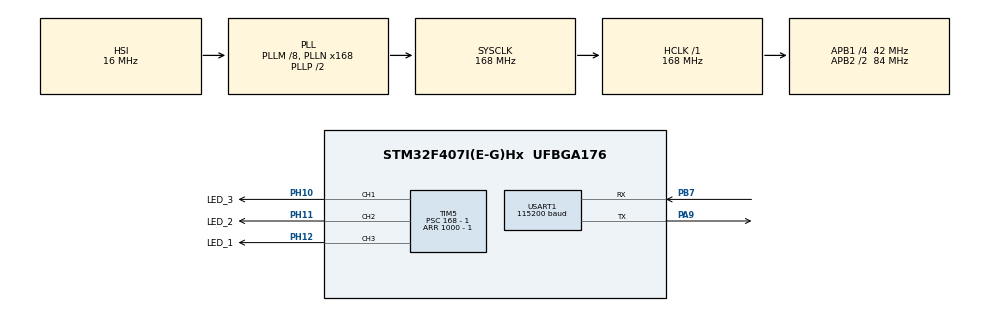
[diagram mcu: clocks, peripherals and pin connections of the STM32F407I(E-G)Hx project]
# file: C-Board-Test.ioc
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Dma.Request0=USART1_RX
Dma.Request1=USART1_TX
Dma.USART1_RX.0.Direction=DMA_PERIPH_TO_MEMORY
Dma.USART1_RX.0.FIFOMode=DMA_FIFOMODE_DISABLE
Dma.USART1_RX.0.Instance=DMA2_Stream2
Dma.USART1_RX.0.MemDataAlignment=DMA_MDATAALIGN_BYTE
Dma.USART1_RX.0.MemInc=DMA_MINC_ENABLE
Dma.USART1_RX.0.Mode=DMA_NORMAL
Dma.USART1_RX.0.PeriphDataAlignment=DMA_PDATAALIGN_BYTE
Dma.USART1_RX.0.PeriphInc=DMA_PINC_DISABLE
Dma.USART1_RX.0.Priority=DMA_PRIORITY_HIGH
Dma.USART1_TX.1.Direction=DMA_MEMORY_TO_PERIPH
Dma.USART1_TX.1.FIFOMode=DMA_FIFOMODE_DISABLE
Dma.USART1_TX.1.Instance=DMA2_Stream7
Dma.USART1_TX.1.MemDataAlignment=DMA_MDATAALIGN_BYTE
Dma.USART1_TX.1.MemInc=DMA_MINC_ENABLE
Dma.USART1_TX.1.Mode=DMA_NORMAL
Dma.USART1_TX.1.PeriphDataAlignment=DMA_PDATAALIGN_BYTE
Dma.USART1_TX.1.PeriphInc=DMA_PINC_DISABLE
Dma.USART1_TX.1.Priority=DMA_PRIORITY_HIGH
FREERTOS.Tasks01=defaultTask,24,128,StartDefaultTask,Default,NULL,Dynamic,NULL,NULL;Breath_LED,24,128,Breath_LED_Loop,As external,NULL,Dynamic,NULL,NULL;Messager,40,128,Messager_Loop,As external,NULL,Dynamic,NULL,NULL;Motion,24,128,Motion_Loop,As external,NULL,Dynamic,NULL,NULL;Light,24,128,Light_Loop,As external,NULL,Dynamic,NULL,NULL;Tof,48,128,Tof_Loop,As external,NULL,Dynamic,NULL,NULL
FREERTOS.configENABLE_FPU=1
FREERTOS.configUSE_NEWLIB_REENTRANT=1
Mcu.Family=STM32F4
Mcu.Name=STM32F407I(E-G)Hx
Mcu.Package=UFBGA176
NVIC.DMA2_Stream2_IRQn=true\:5\:0\:false\:false\:true\:true\:false\:true\:true
NVIC.DMA2_Stream7_IRQn=true\:5\:0\:false\:false\:true\:true\:false\:true\:true
NVIC.PriorityGroup=NVIC_PRIORITYGROUP_4
NVIC.TIM8_TRG_COM_TIM14_IRQn=true\:15\:0\:false\:false\:true\:false\:false\:true\:true
NVIC.TimeBase=TIM8_TRG_COM_TIM14_IRQn
NVIC.TimeBaseIP=TIM14
NVIC.USART1_IRQn=true\:5\:0\:false\:false\:true\:true\:true\:true\:true
PA13.Mode=Serial_Wire
PA13.Signal=SYS_JTMS-SWDIO
PA14.Mode=Serial_Wire
PA14.Signal=SYS_JTCK-SWCLK
PA9.Mode=Asynchronous
PA9.Signal=USART1_TX
PB7.Mode=Asynchronous
PB7.Signal=USART1_RX
PH0-OSC_IN.Mode=HSE-External-Oscillator
PH0-OSC_IN.Signal=RCC_OSC_IN
PH1-OSC_OUT.Mode=HSE-External-Oscillator
PH1-OSC_OUT.Signal=RCC_OSC_OUT
PH10.GPIO_Label=LED_3
PH10.Signal=S_TIM5_CH1
PH11.GPIO_Label=LED_2
PH11.Signal=S_TIM5_CH2
PH12.GPIO_Label=LED_1
PH12.Signal=S_TIM5_CH3
ProjectManager.HeapSize=0x200
ProjectManager.StackSize=0x400
ProjectManager.TargetToolchain=STM32CubeIDE
RCC.48MHZClocksFreq_Value=84000000
RCC.AHBFreq_Value=168000000
RCC.APB1CLKDivider=RCC_HCLK_DIV4
RCC.APB1Freq_Value=42000000
RCC.APB1TimFreq_Value=84000000
RCC.APB2CLKDivider=RCC_HCLK_DIV2
RCC.APB2Freq_Value=84000000
RCC.APB2TimFreq_Value=168000000
RCC.CortexFreq_Value=168000000
RCC.HCLKFreq_Value=168000000
RCC.HSE_VALUE=25000000
RCC.HSI_VALUE=16000000
RCC.LSE_VALUE=32768
RCC.PLLM=8
RCC.PLLN=168
RCC.SYSCLKFreq_VALUE=168000000
RCC.SYSCLKSource=RCC_SYSCLKSOURCE_PLLCLK
RCC.VCOOutputFreq_Value=336000000
SH.S_TIM5_CH1.0=TIM5_CH1,PWM Generation1 CH1
SH.S_TIM5_CH2.0=TIM5_CH2,PWM Generation2 CH2
SH.S_TIM5_CH3.0=TIM5_CH3,PWM Generation3 CH3
TIM5.AutoReloadPreload=TIM_AUTORELOAD_PRELOAD_ENABLE
TIM5.Channel-PWM\ Generation1\ CH1=TIM_CHANNEL_1
TIM5.Channel-PWM\ Generation2\ CH2=TIM_CHANNEL_2
TIM5.Channel-PWM\ Generation3\ CH3=TIM_CHANNEL_3
TIM5.Period=1000 - 1
TIM5.Prescaler=168 - 1
USART1.BaudRate=115200
USART1.VirtualMode=VM_ASYNC
VP_FREERTOS_VS_CMSIS_V2.Mode=CMSIS_V2
VP_SYS_VS_tim14.Mode=TIM14
VP_TIM5_VS_ClockSourceINT.Mode=Internal
board=custom

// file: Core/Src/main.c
/* USER CODE BEGIN Header */
/**
 ******************************************************************************
 * @file           : main.c
 * @brief          : Main program body
 ******************************************************************************
 * @attention
 *
 * Copyright (c) 2023 STMicroelectronics.
 * All rights reserved.
 *
 * This software is licensed under terms that can be found in the LICENSE file
 * in the root directory of this software component.
 * If no LICENSE file comes with this software, it is provided AS-IS.
 *
 ******************************************************************************
 */
/* USER CODE END Header */
#include "main.h"
#include "cmsis_os.h"
#include "dma.h"
#include "tim.h"
#include "usart.h"
#include "gpio.h"

void SystemClock_Config(void);
void MX_FREERTOS_Init(void);

int main(void)
{

    /* MCU Configuration--------------------------------------------------------*/

    /* Reset of all peripherals, Initializes the Flash interface and the Systick. */
    HAL_Init();

    /* Configure the system clock */
    SystemClock_Config();

    /* Initialize all configured peripherals */
    MX_GPIO_Init();
    MX_DMA_Init();
    MX_TIM5_Init();
    MX_USART1_UART_Init();
    /* USER CODE BEGIN 2 */
    HAL_TIM_PWM_Start(&htim5, TIM_CHANNEL_1);
    HAL_TIM_PWM_Start(&htim5, TIM_CHANNEL_2);
    HAL_TIM_PWM_Start(&htim5, TIM_CHANNEL_3);

    /* USER CODE END 2 */

    /* Init scheduler */
    osKernelInitialize(); /* Call init function for freertos objects (in freertos.c) */
    MX_FREERTOS_Init();

    /* Start scheduler */
    osKernelStart();

    /* We should never get here as control is now taken by the scheduler */
    /* Infinite loop */
    while (1) {

    }
}

void SystemClock_Config(void)
{
    RCC_OscInitTypeDef RCC_OscInitStruct = {0};
    RCC_ClkInitTypeDef RCC_ClkInitStruct = {0};

    /** Configure the main internal regulator output voltage
     */
    __HAL_RCC_PWR_CLK_ENABLE();
    __HAL_PWR_VOLTAGESCALING_CONFIG(PWR_REGULATOR_VOLTAGE_SCALE1);

    /** Initializes the RCC Oscillators according to the specified parameters
     * in the RCC_OscInitTypeDef structure.
     */
    RCC_OscInitStruct.OscillatorType      = RCC_OSCILLATORTYPE_HSI;
    RCC_OscInitStruct.HSIState            = RCC_HSI_ON;
    RCC_OscInitStruct.HSICalibrationValue = RCC_HSICALIBRATION_DEFAULT;
    RCC_OscInitStruct.PLL.PLLState        = RCC_PLL_ON;
    RCC_OscInitStruct.PLL.PLLSource       = RCC_PLLSOURCE_HSI;
    RCC_OscInitStruct.PLL.PLLM            = 8;
    RCC_OscInitStruct.PLL.PLLN            = 168;
    RCC_OscInitStruct.PLL.PLLP            = RCC_PLLP_DIV2;
    RCC_OscInitStruct.PLL.PLLQ            = 4;
    if (HAL_RCC_OscConfig(&RCC_OscInitStruct) != HAL_OK) {
        Error_Handler();
    }

    /** Initializes the CPU, AHB and APB buses clocks
     */
    RCC_ClkInitStruct.ClockType      = RCC_CLOCKTYPE_HCLK | RCC_CLOCKTYPE_SYSCLK | RCC_CLOCKTYPE_PCLK1 | RCC_CLOCKTYPE_PCLK2;
    RCC_ClkInitStruct.SYSCLKSource   = RCC_SYSCLKSOURCE_PLLCLK;
    RCC_ClkInitStruct.AHBCLKDivider  = RCC_SYSCLK_DIV1;
    RCC_ClkInitStruct.APB1CLKDivider = RCC_HCLK_DIV4;
    RCC_ClkInitStruct.APB2CLKDivider = RCC_HCLK_DIV2;

    if (HAL_RCC_ClockConfig(&RCC_ClkInitStruct, FLASH_LATENCY_5) != HAL_OK) {
        Error_Handler();
    }
}

void HAL_TIM_PeriodElapsedCallback(TIM_HandleTypeDef *htim)
{
    if (htim->Instance == TIM14) {
        HAL_IncTick();
    }
}

void Error_Handler(void)
{
    __disable_irq();
    while (1) {
    }
}

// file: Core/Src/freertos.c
/* USER CODE BEGIN Header */
/**
 ******************************************************************************
 * File Name          : freertos.c
 * Description        : Code for freertos applications
 ******************************************************************************
 * @attention
 *
 * Copyright (c) 2023 STMicroelectronics.
 * All rights reserved.
 *
 * This software is licensed under terms that can be found in the LICENSE file
 * in the root directory of this software component.
 * If no LICENSE file comes with this software, it is provided AS-IS.
 *
 ******************************************************************************
 */
/* USER CODE END Header */

#include "FreeRTOS.h"
#include "task.h"
#include "main.h"
#include "cmsis_os.h"

/* Definitions for defaultTask */
osThreadId_t defaultTaskHandle;
const osThreadAttr_t defaultTask_attributes = {
  .name = "defaultTask",
  .stack_size = 128 * 4,
  .priority = (osPriority_t) osPriorityNormal,
};
/* Definitions for Breath_LED */
osThreadId_t Breath_LEDHandle;
const osThreadAttr_t Breath_LED_attributes = {
  .name = "Breath_LED",
  .stack_size = 128 * 4,
  .priority = (osPriority_t) osPriorityNormal,
};
/* Definitions for Messager */
osThreadId_t MessagerHandle;
const osThreadAttr_t Messager_attributes = {
  .name = "Messager",
  .stack_size = 128 * 4,
  .priority = (osPriority_t) osPriorityHigh,
};
/* Definitions for Motion */
osThreadId_t MotionHandle;
const osThreadAttr_t Motion_attributes = {
  .name = "Motion",
  .stack_size = 128 * 4,
  .priority = (osPriority_t) osPriorityNormal,
};
/* Definitions for Light */
osThreadId_t LightHandle;
const osThreadAttr_t Light_attributes = {
  .name = "Light",
  .stack_size = 128 * 4,
  .priority = (osPriority_t) osPriorityNormal,
};
/* Definitions for Tof */
osThreadId_t TofHandle;
const osThreadAttr_t Tof_attributes = {
  .name = "Tof",
  .stack_size = 128 * 4,
  .priority = (osPriority_t) osPriorityRealtime,
};

void StartDefaultTask(void *argument);
extern void Breath_LED_Loop(void *argument);
extern void Messager_Loop(void *argument);
extern void Motion_Loop(void *argument);
extern void Light_Loop(void *argument);
extern void Tof_Loop(void *argument);

void MX_FREERTOS_Init(void); /* (MISRA C 2004 rule 8.1) */

void MX_FREERTOS_Init(void) {

  /* Create the thread(s) */
  /* creation of defaultTask */
  defaultTaskHandle = osThreadNew(StartDefaultTask, NULL, &defaultTask_attributes);

  /* creation of Breath_LED */
  Breath_LEDHandle = osThreadNew(Breath_LED_Loop, NULL, &Breath_LED_attributes);

  /* creation of Messager */
  MessagerHandle = osThreadNew(Messager_Loop, NULL, &Messager_attributes);

  /* creation of Motion */
  MotionHandle = osThreadNew(Motion_Loop, NULL, &Motion_attributes);

  /* creation of Light */
  LightHandle = osThreadNew(Light_Loop, NULL, &Light_attributes);

  /* creation of Tof */
  TofHandle = osThreadNew(Tof_Loop, NULL, &Tof_attributes);

}

void StartDefaultTask(void *argument)
{
    for (;;) {
        osDelay(1);
    }
}
